AUTOSAR XML (schema 4-2-2)
package /STELLANTIS/EPT/ASWCs
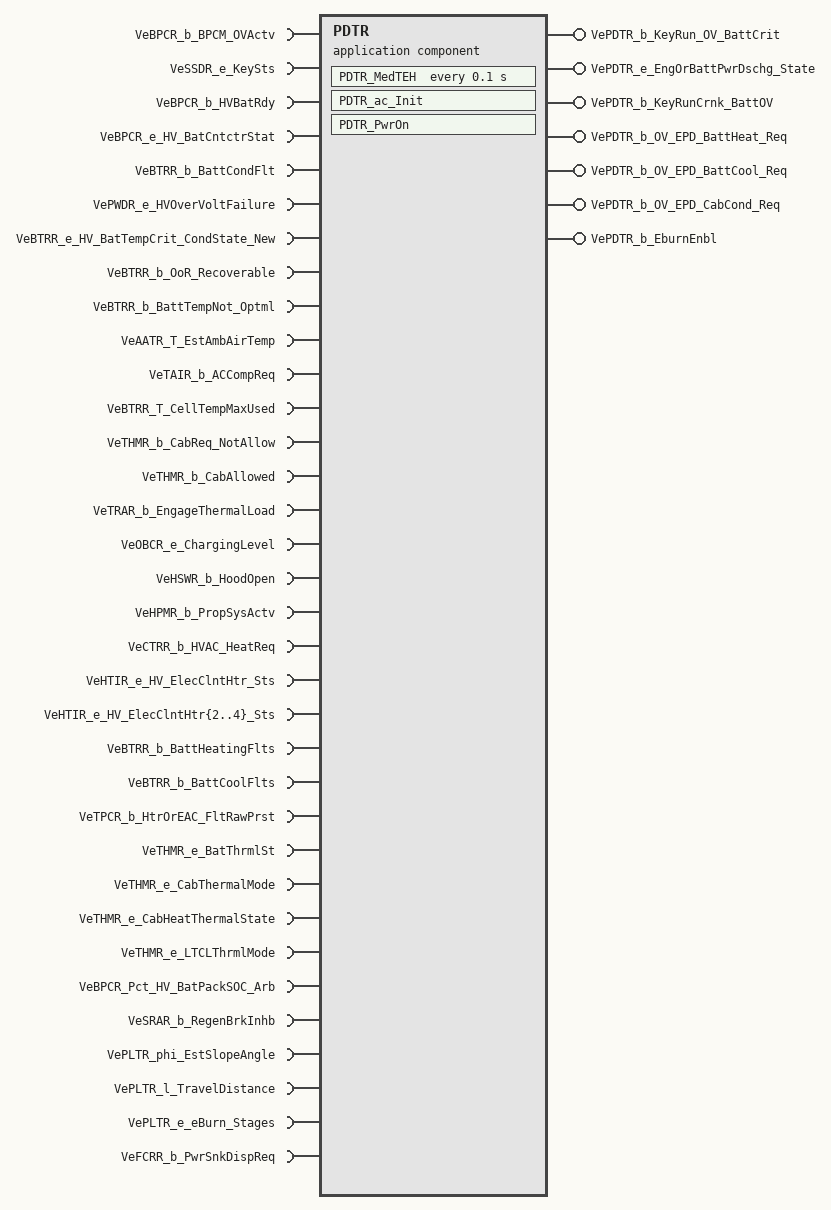
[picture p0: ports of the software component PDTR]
  application sw component type PDTR
    36 x require port:
      VeBPCR_b_BPCM_OVActv: variation-point={short-label=vpVeBPCR_b_BPCM_OVActv, sw-syscond=1}, nonqueued-receiver-com-spec{data-element=Value, init-value=0}, required-interface=VeBPCR_b_BPCM_OVActv
      VeSSDR_e_KeySts: variation-point={short-label=vpVeSSDR_e_KeySts, sw-syscond=1}, nonqueued-receiver-com-spec{data-element=Value, init-value=CeSSDR_e_KeyOff}, required-interface=VeSSDR_e_KeySts
      VeBPCR_b_HVBatRdy: variation-point={short-label=vpVeBPCR_b_HVBatRdy, sw-syscond=1}, nonqueued-receiver-com-spec{data-element=Value, init-value=0}, required-interface=VeBPCR_b_HVBatRdy
      VeBPCR_e_HV_BatCntctrStat: variation-point={short-label=vpVeBPCR_e_HV_BatCntctrStat, sw-syscond=1}, nonqueued-receiver-com-spec{data-element=Value, init-value=CeHVTR_e_Open}, required-interface=VeBPCR_e_HV_BatCntctrStat
      VeBTRR_b_BattCondFlt: variation-point={short-label=vpVeBTRR_b_BattCondFlt, sw-syscond=1}, nonqueued-receiver-com-spec{data-element=Value, init-value=0}, required-interface=VeBTRR_b_BattCondFlt
      VePWDR_e_HVOverVoltFailure: variation-point={short-label=vpVePWDR_e_HVOverVoltFailure, sw-syscond=1}, nonqueued-receiver-com-spec{data-element=Value, init-value=CeHVTR_e_HVOverVoltPass}, required-interface=VePWDR_e_HVOverVoltFailure
      VeBTRR_e_HV_BatTempCrit_CondState_New: variation-point={short-label=vpVeBTRR_e_HV_BatTempCrit_CondState_New, sw-syscond=1}, nonqueued-receiver-com-spec{data-element=Value, init-value=CeBTRR_e_BatNotCrit}, required-interface=VeBTRR_e_HV_BatTempCrit_CondState_New
      VeBTRR_b_OoR_Recoverable: variation-point={short-label=vpVeBTRR_b_OoR_Recoverable, sw-syscond=1}, nonqueued-receiver-com-spec{data-element=Value, init-value=0}, required-interface=VeBTRR_b_OoR_Recoverable
      VeBTRR_b_BattTempNot_Optml: variation-point={short-label=vpVeBTRR_b_BattTempNot_Optml, sw-syscond=1}, nonqueued-receiver-com-spec{data-element=Value, init-value=0}, required-interface=VeBTRR_b_BattTempNot_Optml
      VeAATR_T_EstAmbAirTemp: variation-point={short-label=vpVeAATR_T_EstAmbAirTemp, sw-syscond=1}, nonqueued-receiver-com-spec{data-element=Value, init-value=0}, required-interface=VeAATR_T_EstAmbAirTemp
      VeTAIR_b_ACCompReq: variation-point={short-label=vpVeTAIR_b_ACCompReq, sw-syscond=1}, nonqueued-receiver-com-spec{data-element=Value, init-value=0}, required-interface=VeTAIR_b_ACCompReq
      VeBTRR_T_CellTempMaxUsed: variation-point={short-label=vpVeBTRR_T_CellTempMaxUsed, sw-syscond=1}, nonqueued-receiver-com-spec{data-element=Value, init-value=0}, required-interface=VeBTRR_T_CellTempMaxUsed
      VeTHMR_b_CabReq_NotAllow: variation-point={short-label=vpVeTHMR_b_CabReq_NotAllow, sw-syscond=1}, nonqueued-receiver-com-spec{data-element=Value, init-value=0}, required-interface=VeTHMR_b_CabReq_NotAllow
      VeTHMR_b_CabAllowed: variation-point={short-label=vpVeTHMR_b_CabAllowed, sw-syscond=1}, nonqueued-receiver-com-spec{data-element=Value, init-value=0}, required-interface=VeTHMR_b_CabAllowed
      VeTRAR_b_EngageThermalLoad: variation-point={short-label=vpVeTRAR_b_EngageThermalLoad, sw-syscond=1}, nonqueued-receiver-com-spec{data-element=Value, init-value=0}, required-interface=VeTRAR_b_EngageThermalLoad
      VeOBCR_e_ChargingLevel: variation-point={short-label=vpVeOBCR_e_ChargingLevel, sw-syscond=1}, nonqueued-receiver-com-spec{data-element=Value, init-value=CeOBCR_e_ChargingLvlDefault}, required-interface=VeOBCR_e_ChargingLevel
      VeHSWR_b_HoodOpen: variation-point={short-label=vpVeHSWR_b_HoodOpen, sw-syscond=1}, nonqueued-receiver-com-spec{data-element=Value, init-value=0}, required-interface=VeHSWR_b_HoodOpen
      VeHPMR_b_PropSysActv: variation-point={short-label=vpVeHPMR_b_PropSysActv, sw-syscond=1}, nonqueued-receiver-com-spec{data-element=Value, init-value=0}, required-interface=VeHPMR_b_PropSysActv
      VeCTRR_b_HVAC_HeatReq: variation-point={short-label=vpVeCTRR_b_HVAC_HeatReq, sw-syscond=1}, nonqueued-receiver-com-spec{data-element=Value, init-value=0}, required-interface=VeCTRR_b_HVAC_HeatReq
      VeHTIR_e_HV_ElecClntHtr_Sts: variation-point={short-label=vpVeHTIR_e_HV_ElecClntHtr_Sts, sw-syscond=1}, nonqueued-receiver-com-spec{data-element=Value, init-value=CeHTIR_e_HtrSts_Off}, required-interface=VeHTIR_e_HV_ElecClntHtr_Sts
      VeHTIR_e_HV_ElecClntHtr{2..4}_Sts: variation-point={short-label=vpVeHTIR_e_HV_ElecClntHtr{2..4}_Sts, sw-syscond=1}, nonqueued-receiver-com-spec{data-element=Value, init-value=CeHTIR_e_HtrSts_Off}, required-interface=VeHTIR_e_HV_ElecClntHtr{2..4}_Sts
      VeBTRR_b_BattHeatingFlts: variation-point={short-label=vpVeBTRR_b_BattHeatingFlts, sw-syscond=1}, nonqueued-receiver-com-spec{data-element=Value, init-value=0}, required-interface=VeBTRR_b_BattHeatingFlts
      VeBTRR_b_BattCoolFlts: variation-point={short-label=vpVeBTRR_b_BattCoolFlts, sw-syscond=1}, nonqueued-receiver-com-spec{data-element=Value, init-value=0}, required-interface=VeBTRR_b_BattCoolFlts
      VeTPCR_b_HtrOrEAC_FltRawPrst: variation-point={short-label=vpVeTPCR_b_HtrOrEAC_FltRawPrst, sw-syscond=1}, nonqueued-receiver-com-spec{data-element=Value, init-value=0}, required-interface=VeTPCR_b_HtrOrEAC_FltRawPrst
      VeTHMR_e_BatThrmlSt: variation-point={short-label=vpVeTHMR_e_BatThrmlSt, sw-syscond=1}, nonqueued-receiver-com-spec{data-element=Value, init-value=CeTHMR_e_NoConditioning}, required-interface=VeTHMR_e_BatThrmlSt
      VeTHMR_e_CabThermalMode: variation-point={short-label=vpVeTHMR_e_CabThermalMode, sw-syscond=1}, nonqueued-receiver-com-spec{data-element=Value, init-value=CeTHMR_e_Cab_NoConditioning}, required-interface=VeTHMR_e_CabThermalMode
      VeTHMR_e_CabHeatThermalState: variation-point={short-label=vpVeTHMR_e_CabHeatThermalState, sw-syscond=1}, nonqueued-receiver-com-spec{data-element=Value, init-value=CeTHMR_e_NoCabinHeating}, required-interface=VeTHMR_e_CabHeatThermalState
      VeTHMR_e_LTCLThrmlMode: variation-point={short-label=vpVeTHMR_e_LTCLThrmlMode, sw-syscond=1}, nonqueued-receiver-com-spec{data-element=Value, init-value=CeTHMR_e_LTCLBalancing}, required-interface=VeTHMR_e_LTCLThrmlMode
      VeBPCR_Pct_HV_BatPackSOC_Arb: variation-point={short-label=vpVeBPCR_Pct_HV_BatPackSOC_Arb, sw-syscond=1}, nonqueued-receiver-com-spec{data-element=Value, init-value=0}, required-interface=VeBPCR_Pct_HV_BatPackSOC_Arb
      VeSRAR_b_RegenBrkInhb: variation-point={short-label=vpVeSRAR_b_RegenBrkInhb, sw-syscond=1}, nonqueued-receiver-com-spec{data-element=Value, init-value=0}, required-interface=VeSRAR_b_RegenBrkInhb
      VePLTR_phi_EstSlopeAngle: variation-point={short-label=vpVePLTR_phi_EstSlopeAngle, sw-syscond=1}, nonqueued-receiver-com-spec{data-element=Value, init-value=0}, required-interface=VePLTR_phi_EstSlopeAngle
      VePLTR_l_TravelDistance: variation-point={short-label=vpVePLTR_l_TravelDistance, sw-syscond=1}, nonqueued-receiver-com-spec{data-element=Value, init-value=0}, required-interface=VePLTR_l_TravelDistance
      VePLTR_e_eBurn_Stages: variation-point={short-label=vpVePLTR_e_eBurn_Stages, sw-syscond=1}, nonqueued-receiver-com-spec{data-element=Value, init-value=CePLTR_e_eBurn_NormalStage}, required-interface=VePLTR_e_eBurn_Stages
      VeFCRR_b_PwrSnkDispReq: variation-point={short-label=vpVeFCRR_b_PwrSnkDispReq, sw-syscond=1}, nonqueued-receiver-com-spec{data-element=Value, init-value=0}, required-interface=VeFCRR_b_PwrSnkDispReq
    7 x provide port:
      VePDTR_b_KeyRun_OV_BattCrit: variation-point={short-label=vpVePDTR_b_KeyRun_OV_BattCrit, sw-syscond=1}, nonqueued-sender-com-spec{data-element=Value, init-value=0}, provided-interface=VePDTR_b_KeyRun_OV_BattCrit
      VePDTR_e_EngOrBattPwrDschg_State: variation-point={short-label=vpVePDTR_e_EngOrBattPwrDschg_State, sw-syscond=1}, nonqueued-sender-com-spec{data-element=Value, init-value=CePDTR_e_No_Dischrg}, provided-interface=VePDTR_e_EngOrBattPwrDschg_State
      VePDTR_b_KeyRunCrnk_BattOV: variation-point={short-label=vpVePDTR_b_KeyRunCrnk_BattOV, sw-syscond=1}, nonqueued-sender-com-spec{data-element=Value, init-value=0}, provided-interface=VePDTR_b_KeyRunCrnk_BattOV
      VePDTR_b_OV_EPD_BattHeat_Req: variation-point={short-label=vpVePDTR_b_OV_EPD_BattHeat_Req, sw-syscond=1}, nonqueued-sender-com-spec{data-element=Value, init-value=0}, provided-interface=VePDTR_b_OV_EPD_BattHeat_Req
      VePDTR_b_OV_EPD_BattCool_Req: variation-point={short-label=vpVePDTR_b_OV_EPD_BattCool_Req, sw-syscond=1}, nonqueued-sender-com-spec{data-element=Value, init-value=0}, provided-interface=VePDTR_b_OV_EPD_BattCool_Req
      VePDTR_b_OV_EPD_CabCond_Req: variation-point={short-label=vpVePDTR_b_OV_EPD_CabCond_Req, sw-syscond=1}, nonqueued-sender-com-spec{data-element=Value, init-value=0}, provided-interface=VePDTR_b_OV_EPD_CabCond_Req
      VePDTR_b_EburnEnbl: variation-point={short-label=vpVePDTR_b_EburnEnbl, sw-syscond=1}, nonqueued-sender-com-spec{data-element=Value, init-value=0}, provided-interface=VePDTR_b_EburnEnbl
    behavior IB_PDTR: data-type-mapping=msADTtoIDTMapping, handle-termination-and-restart=NO-SUPPORT
      timing event Event_MedTEH: start-on-event=PDTR_MedTEH, period=0.1
      init event Event_PDTR_ac_Init: start-on-event=PDTR_ac_Init
      init event Event_PwrOn: start-on-event=PDTR_PwrOn
      runnable PDTR_ac_Init
        data-send-points:
          access OUT_VePDTR_e_EngOrBattPwrDschg_State_Value: accessed-variable=VePDTR_e_EngOrBattPwrDschg_State.Value, variation-point={short-label=vpOUT_VePDTR_e_EngOrBattPwrDschg_State_Value, sw-syscond=1}
      runnable PDTR_PwrOn: variation-point={short-label=vpPDTR_PwrOn, sw-syscond=1}
        data-send-points:
          7 x access:
            OUT_VePDTR_b_KeyRun_OV_BattCrit_Value: accessed-variable=VePDTR_b_KeyRun_OV_BattCrit.Value, variation-point={short-label=vpOUT_VePDTR_b_KeyRun_OV_BattCrit_Value, sw-syscond=1}
            OUT_VePDTR_e_EngOrBattPwrDschg_State_Value: accessed-variable=VePDTR_e_EngOrBattPwrDschg_State.Value, variation-point={short-label=vpOUT_VePDTR_e_EngOrBattPwrDschg_State_Value, sw-syscond=1}
            OUT_VePDTR_b_KeyRunCrnk_BattOV_Value: accessed-variable=VePDTR_b_KeyRunCrnk_BattOV.Value, variation-point={short-label=vpOUT_VePDTR_b_KeyRunCrnk_BattOV_Value, sw-syscond=1}
            OUT_VePDTR_b_OV_EPD_BattHeat_Req_Value: accessed-variable=VePDTR_b_OV_EPD_BattHeat_Req.Value, variation-point={short-label=vpOUT_VePDTR_b_OV_EPD_BattHeat_Req_Value, sw-syscond=1}
            OUT_VePDTR_b_OV_EPD_BattCool_Req_Value: accessed-variable=VePDTR_b_OV_EPD_BattCool_Req.Value, variation-point={short-label=vpOUT_VePDTR_b_OV_EPD_BattCool_Req_Value, sw-syscond=1}
            OUT_VePDTR_b_OV_EPD_CabCond_Req_Value: accessed-variable=VePDTR_b_OV_EPD_CabCond_Req.Value, variation-point={short-label=vpOUT_VePDTR_b_OV_EPD_CabCond_Req_Value, sw-syscond=1}
            OUT_VePDTR_b_EburnEnbl_Value: accessed-variable=VePDTR_b_EburnEnbl.Value, variation-point={short-label=vpOUT_VePDTR_b_EburnEnbl_Value, sw-syscond=1}
      runnable PDTR_MedTEH: variation-point={short-label=vpPDTR_MedTEH, sw-syscond=1}
        data-receive-point-by-arguments:
          36 x access:
            IN_VeAATR_T_EstAmbAirTemp_Value: accessed-variable=VeAATR_T_EstAmbAirTemp.Value, variation-point={short-label=vpIN_VeAATR_T_EstAmbAirTemp_Value, sw-syscond=1}
            IN_VeBPCR_Pct_HV_BatPackSOC_Arb_Value: accessed-variable=VeBPCR_Pct_HV_BatPackSOC_Arb.Value, variation-point={short-label=vpIN_VeBPCR_Pct_HV_BatPackSOC_Arb_Value, sw-syscond=1}
            IN_VeBPCR_b_BPCM_OVActv_Value: accessed-variable=VeBPCR_b_BPCM_OVActv.Value, variation-point={short-label=vpIN_VeBPCR_b_BPCM_OVActv_Value, sw-syscond=1}
            IN_VeBPCR_b_HVBatRdy_Value: accessed-variable=VeBPCR_b_HVBatRdy.Value, variation-point={short-label=vpIN_VeBPCR_b_HVBatRdy_Value, sw-syscond=1}
            IN_VeBPCR_e_HV_BatCntctrStat_Value: accessed-variable=VeBPCR_e_HV_BatCntctrStat.Value, variation-point={short-label=vpIN_VeBPCR_e_HV_BatCntctrStat_Value, sw-syscond=1}
            IN_VeBTRR_T_CellTempMaxUsed_Value: accessed-variable=VeBTRR_T_CellTempMaxUsed.Value, variation-point={short-label=vpIN_VeBTRR_T_CellTempMaxUsed_Value, sw-syscond=1}
            IN_VeBTRR_b_BattCondFlt_Value: accessed-variable=VeBTRR_b_BattCondFlt.Value, variation-point={short-label=vpIN_VeBTRR_b_BattCondFlt_Value, sw-syscond=1}
            IN_VeBTRR_b_BattCoolFlts_Value: accessed-variable=VeBTRR_b_BattCoolFlts.Value, variation-point={short-label=vpIN_VeBTRR_b_BattCoolFlts_Value, sw-syscond=1}
            IN_VeBTRR_b_BattHeatingFlts_Value: accessed-variable=VeBTRR_b_BattHeatingFlts.Value, variation-point={short-label=vpIN_VeBTRR_b_BattHeatingFlts_Value, sw-syscond=1}
            IN_VeBTRR_b_BattTempNot_Optml_Value: accessed-variable=VeBTRR_b_BattTempNot_Optml.Value, variation-point={short-label=vpIN_VeBTRR_b_BattTempNot_Optml_Value, sw-syscond=1}
            IN_VeBTRR_b_OoR_Recoverable_Value: accessed-variable=VeBTRR_b_OoR_Recoverable.Value, variation-point={short-label=vpIN_VeBTRR_b_OoR_Recoverable_Value, sw-syscond=1}
            IN_VeBTRR_e_HV_BatTempCrit_CondState_New_Value: accessed-variable=VeBTRR_e_HV_BatTempCrit_CondState_New.Value, variation-point={short-label=vpIN_VeBTRR_e_HV_BatTempCrit_CondState_New_Value, sw-syscond=1}
            IN_VeCTRR_b_HVAC_HeatReq_Value: accessed-variable=VeCTRR_b_HVAC_HeatReq.Value, variation-point={short-label=vpIN_VeCTRR_b_HVAC_HeatReq_Value, sw-syscond=1}
            IN_VeFCRR_b_PwrSnkDispReq_Value: accessed-variable=VeFCRR_b_PwrSnkDispReq.Value, variation-point={short-label=vpIN_VeFCRR_b_PwrSnkDispReq_Value, sw-syscond=1}
            IN_VeHPMR_b_PropSysActv_Value: accessed-variable=VeHPMR_b_PropSysActv.Value, variation-point={short-label=vpIN_VeHPMR_b_PropSysActv_Value, sw-syscond=1}
            IN_VeHSWR_b_HoodOpen_Value: accessed-variable=VeHSWR_b_HoodOpen.Value, variation-point={short-label=vpIN_VeHSWR_b_HoodOpen_Value, sw-syscond=1}
            IN_VeHTIR_e_HV_ElecClntHtr{2..4}_Sts_Value: accessed-variable=VeHTIR_e_HV_ElecClntHtr{2..4}_Sts.Value, variation-point={short-label=vpIN_VeHTIR_e_HV_ElecClntHtr{2..4}_Sts_Value, sw-syscond=1}
            IN_VeHTIR_e_HV_ElecClntHtr_Sts_Value: accessed-variable=VeHTIR_e_HV_ElecClntHtr_Sts.Value, variation-point={short-label=vpIN_VeHTIR_e_HV_ElecClntHtr_Sts_Value, sw-syscond=1}
            IN_VeOBCR_e_ChargingLevel_Value: accessed-variable=VeOBCR_e_ChargingLevel.Value, variation-point={short-label=vpIN_VeOBCR_e_ChargingLevel_Value, sw-syscond=1}
            IN_VePLTR_e_eBurn_Stages_Value: accessed-variable=VePLTR_e_eBurn_Stages.Value, variation-point={short-label=vpIN_VePLTR_e_eBurn_Stages_Value, sw-syscond=1}
            IN_VePLTR_l_TravelDistance_Value: accessed-variable=VePLTR_l_TravelDistance.Value, variation-point={short-label=vpIN_VePLTR_l_TravelDistance_Value, sw-syscond=1}
            IN_VePLTR_phi_EstSlopeAngle_Value: accessed-variable=VePLTR_phi_EstSlopeAngle.Value, variation-point={short-label=vpIN_VePLTR_phi_EstSlopeAngle_Value, sw-syscond=1}
            IN_VePWDR_e_HVOverVoltFailure_Value: accessed-variable=VePWDR_e_HVOverVoltFailure.Value, variation-point={short-label=vpIN_VePWDR_e_HVOverVoltFailure_Value, sw-syscond=1}
            IN_VeSRAR_b_RegenBrkInhb_Value: accessed-variable=VeSRAR_b_RegenBrkInhb.Value, variation-point={short-label=vpIN_VeSRAR_b_RegenBrkInhb_Value, sw-syscond=1}
            IN_VeSSDR_e_KeySts_Value: accessed-variable=VeSSDR_e_KeySts.Value, variation-point={short-label=vpIN_VeSSDR_e_KeySts_Value, sw-syscond=1}
            IN_VeTAIR_b_ACCompReq_Value: accessed-variable=VeTAIR_b_ACCompReq.Value, variation-point={short-label=vpIN_VeTAIR_b_ACCompReq_Value, sw-syscond=1}
            IN_VeTHMR_b_CabAllowed_Value: accessed-variable=VeTHMR_b_CabAllowed.Value, variation-point={short-label=vpIN_VeTHMR_b_CabAllowed_Value, sw-syscond=1}
            IN_VeTHMR_b_CabReq_NotAllow_Value: accessed-variable=VeTHMR_b_CabReq_NotAllow.Value, variation-point={short-label=vpIN_VeTHMR_b_CabReq_NotAllow_Value, sw-syscond=1}
            IN_VeTHMR_e_BatThrmlSt_Value: accessed-variable=VeTHMR_e_BatThrmlSt.Value, variation-point={short-label=vpIN_VeTHMR_e_BatThrmlSt_Value, sw-syscond=1}
            IN_VeTHMR_e_CabHeatThermalState_Value: accessed-variable=VeTHMR_e_CabHeatThermalState.Value, variation-point={short-label=vpIN_VeTHMR_e_CabHeatThermalState_Value, sw-syscond=1}
            IN_VeTHMR_e_CabThermalMode_Value: accessed-variable=VeTHMR_e_CabThermalMode.Value, variation-point={short-label=vpIN_VeTHMR_e_CabThermalMode_Value, sw-syscond=1}
            IN_VeTHMR_e_LTCLThrmlMode_Value: accessed-variable=VeTHMR_e_LTCLThrmlMode.Value, variation-point={short-label=vpIN_VeTHMR_e_LTCLThrmlMode_Value, sw-syscond=1}
            IN_VeTPCR_b_HtrOrEAC_FltRawPrst_Value: accessed-variable=VeTPCR_b_HtrOrEAC_FltRawPrst.Value, variation-point={short-label=vpIN_VeTPCR_b_HtrOrEAC_FltRawPrst_Value, sw-syscond=1}
            IN_VeTRAR_b_EngageThermalLoad_Value: accessed-variable=VeTRAR_b_EngageThermalLoad.Value, variation-point={short-label=vpIN_VeTRAR_b_EngageThermalLoad_Value, sw-syscond=1}
        data-send-points:
          7 x access:
            OUT_VePDTR_b_KeyRun_OV_BattCrit_Value: accessed-variable=VePDTR_b_KeyRun_OV_BattCrit.Value, variation-point={short-label=vpOUT_VePDTR_b_KeyRun_OV_BattCrit_Value, sw-syscond=1}
            OUT_VePDTR_e_EngOrBattPwrDschg_State_Value: accessed-variable=VePDTR_e_EngOrBattPwrDschg_State.Value, variation-point={short-label=vpOUT_VePDTR_e_EngOrBattPwrDschg_State_Value, sw-syscond=1}
            OUT_VePDTR_b_KeyRunCrnk_BattOV_Value: accessed-variable=VePDTR_b_KeyRunCrnk_BattOV.Value, variation-point={short-label=vpOUT_VePDTR_b_KeyRunCrnk_BattOV_Value, sw-syscond=1}
            OUT_VePDTR_b_OV_EPD_BattHeat_Req_Value: accessed-variable=VePDTR_b_OV_EPD_BattHeat_Req.Value, variation-point={short-label=vpOUT_VePDTR_b_OV_EPD_BattHeat_Req_Value, sw-syscond=1}
            OUT_VePDTR_b_OV_EPD_BattCool_Req_Value: accessed-variable=VePDTR_b_OV_EPD_BattCool_Req.Value, variation-point={short-label=vpOUT_VePDTR_b_OV_EPD_BattCool_Req_Value, sw-syscond=1}
            OUT_VePDTR_b_OV_EPD_CabCond_Req_Value: accessed-variable=VePDTR_b_OV_EPD_CabCond_Req.Value, variation-point={short-label=vpOUT_VePDTR_b_OV_EPD_CabCond_Req_Value, sw-syscond=1}
            OUT_VePDTR_b_EburnEnbl_Value: accessed-variable=VePDTR_b_EburnEnbl.Value, variation-point={short-label=vpOUT_VePDTR_b_EburnEnbl_Value, sw-syscond=1}
      variation point proxy Variant_PDTR_1: category=CONDITION, condition-access=1
